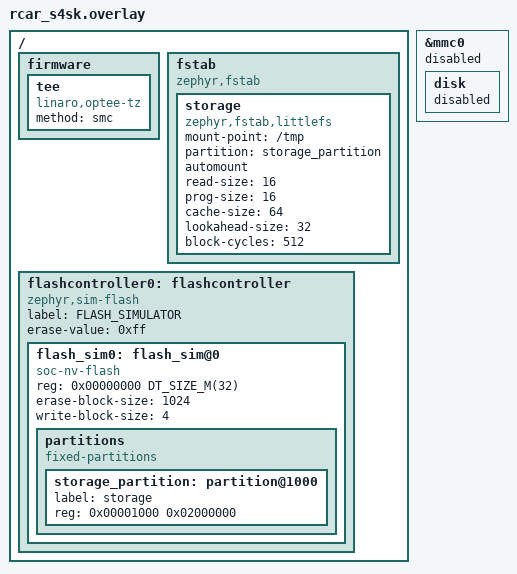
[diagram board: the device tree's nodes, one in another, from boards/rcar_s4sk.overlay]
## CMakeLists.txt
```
#
# Copyright (C) 2023 Renesas Electronics Corporation.
# Copyright (C) 2023 EPAM Systems, Inc.
#
# SPDX-License-Identifier: Apache-2.0
#

cmake_minimum_required(VERSION 3.20.0)

find_package(Zephyr REQUIRED HINTS $ENV{ZEPHYR_BASE})

include($ENV{ZEPHYR_BASE}/cmake/app/boilerplate.cmake NO_POLICY_SCOPE)

project(aoszephyrapp)

# ######################################################################################################################
# Includes
# ######################################################################################################################

zephyr_include_directories(${CMAKE_CURRENT_BINARY_DIR} src)

if(CONFIG_BOARD MATCHES "rcar")
    zephyr_include_directories(${CMAKE_CURRENT_BINARY_DIR} prebuilt)
endif()

if(BOARD MATCHES "native_posix*")
    zephyr_include_directories(${CMAKE_CURRENT_BINARY_DIR} mocks/include)
endif()

if(TA_DEPLOY_DIR)
    set(TA_BIN_DIRECTORY ta_bin)
    set(GENERATED_DIRECTORY ta_table)
    execute_process(
        COMMAND ${CMAKE_CURRENT_SOURCE_DIR}/scripts/prepare_ta.sh -t ${CMAKE_CURRENT_SOURCE_DIR} -f ${TA_DEPLOY_DIR} -b
                ${TA_BIN_DIRECTORY} -g ${GENERATED_DIRECTORY}
    )
    include_directories(app PRIVATE ${CMAKE_CURRENT_SOURCE_DIR}/${TA_BIN_DIRECTORY})
    target_sources(app PRIVATE ${GENERATED_DIRECTORY}/ta_table.c ${GENERATED_DIRECTORY}/ta_table.S)
endif()

# ######################################################################################################################
# Definitions
# ######################################################################################################################

# Aos core configuration
add_definitions(-include aoscoreconfig.hpp)

# ######################################################################################################################
# Compile options
# ######################################################################################################################

# Add stack usage warning
target_compile_options(app PRIVATE -Wstack-usage=2048)

# ######################################################################################################################
# Taget
# ######################################################################################################################

target_sources(
    app
    PRIVATE src/main.cpp
            src/logger/logger.cpp
            src/app/app.cpp
            src/cmclient/cmclient.cpp
            src/runner/runner.cpp
            src/storage/storage.cpp
            src/downloader/downloader.cpp
            src/resourcemanager/resourcemanager.cpp
            src/ocispec/ocispec.cpp
            src/resourceusageprovider/resourceusageprovider.cpp
            src/utils/checksum.cpp
)

# Enable vchannels and xrun mocks for native posix
target_sources_ifdef(CONFIG_NATIVE_APPLICATION app PRIVATE mocks/vch/vch.cpp mocks/xrun/xrun.cpp mocks/xstat/xstat.cpp)

# NOTE: Include source files with DomD binaries and configuration, needed to start DomD on Zephyr
target_sources_ifdef(
    CONFIG_BOARD_RCAR_SPIDER app PRIVATE src/domains/domd/domd_cfg_spider.c src/domains/domd/domain_bins_spider.S
)

target_sources_ifdef(
    CONFIG_BOARD_RCAR_S4SK app PRIVATE src/domains/domd/domd_cfg_s4sk.c src/domains/domd/domain_bins_s4sk.S
)

# NOTE: Include source files for DomD support for Gen3 board.
# Gen3 specific binaries were added with separate .S file to avoid extra checks inside source files.
target_sources_ifdef(
    CONFIG_BOARD_RCAR_SALVATOR_XS_M3 app PRIVATE src/domains/domd/domd_cfg_salvator_xs.c
    src/domains/domd/domain_bins_gen3.S
)

target_sources_ifdef(
    CONFIG_BOARD_RCAR_H3ULCB_CA57 app PRIVATE src/domains/domd/domd_cfg_h3ulcb.c src/domains/domd/domain_bins_gen3.S
)

# NOTE: Include source files for qemu boards.
target_sources_ifdef(CONFIG_BOARD_QEMU_CORTEX_A53 app PRIVATE src/domains/domd/domd_cfg_xenvm.c)

# NOTE: Include HW-specific source file
# target_sources_ifndef(CONFIG_NATIVE_APPLICATION app PRIVATE src/bsp/reboot.c src/bsp/mount.c)
target_sources_ifndef(CONFIG_NATIVE_APPLICATION app PRIVATE src/bsp/reboot.c)

# ######################################################################################################################
# Versioning
# ######################################################################################################################

find_package(Git)

if(NOT GIT_FOUND)
    set(GIT_EXECUTABLE git)
endif()

set(CMAKE_MODULE_PATH ${PROJECT_SOURCE_DIR}/CMakeModules)

add_custom_target(
    version
    COMMAND
        ${CMAKE_COMMAND} -D GIT_EXECUTABLE=${GIT_EXECUTABLE} -D INPUT_FILE=${CMAKE_SOURCE_DIR}/src/version.hpp.in -D
        OUTPUT_FILE=${CMAKE_CURRENT_BINARY_DIR}/version.hpp -D GIT_SOURCE_DIR=${CMAKE_SOURCE_DIR} -P
        ${CMAKE_MODULE_PATH}/GenerateVersion.cmake
)

add_dependencies(app version)

# ######################################################################################################################
#  Generate API
# ######################################################################################################################

find_package(CoreAPI)

generate_api(${CMAKE_CURRENT_SOURCE_DIR}/../aos_core_api)

# ######################################################################################################################
# External libs
# ######################################################################################################################

include(ExternalProject)

zephyr_get_include_directories_for_lang_as_string(CXX includes)
zephyr_get_system_include_directories_for_lang_as_string(CXX system_includes)
zephyr_get_compile_definitions_for_lang_as_string(CXX definitions)
zephyr_get_compile_options_for_lang_as_string(CXX options)

set(external_project_cxx_flags "${includes} ${system_includes} ${definitions} ${options}")

# ######################################################################################################################
# aos_core_lib_cpp
# ######################################################################################################################

set(aos_cxx_flags "${external_project_cxx_flags} -Wno-pedantic -Wno-error -include aoscoreconfig.hpp")
set(aoscore_build_dir ${CMAKE_CURRENT_BINARY_DIR}/aoscore)

ExternalProject_Add(
    aoscore
    PREFIX ${aoscore_build_dir}
    CMAKE_ARGS -DCMAKE_INSTALL_PREFIX=${aoscore_build_dir} -DCMAKE_C_COMPILER=${CMAKE_C_COMPILER}
               -DCMAKE_CXX_COMPILER=${CMAKE_CXX_COMPILER} -DCMAKE_SYSTEM_NAME=${CMAKE_SYSTEM_NAME}
               -DCMAKE_SYSTEM_PROCESSOR=${CMAKE_SYSTEM_PROCESSOR} -DCMAKE_CXX_FLAGS=${aos_cxx_flags}
    SOURCE_DIR ${APPLICATION_SOURCE_DIR}/../aos_core_lib_cpp
    BUILD_BYPRODUCTS ${aoscore_build_dir}/lib/libaossmcpp.a ${aoscore_build_dir}/lib/libaosiamcpp.a
                     ${aoscore_build_dir}/lib/libaoscommoncpp.a
    DEPENDS zephyr_interface
)

# aoscommon
add_library(aoscommon STATIC IMPORTED GLOBAL)

add_dependencies(aoscommon aoscore)

set_target_properties(aoscommon PROPERTIES IMPORTED_LOCATION ${aoscore_build_dir}/lib/libaoscommoncpp.a)
set_target_properties(aoscommon PROPERTIES INTERFACE_INCLUDE_DIRECTORIES ${aoscore_build_dir}/include)

target_link_libraries(app PUBLIC aoscommon)

# aossm
file(MAKE_DIRECTORY ${aoscore_build_dir}/include)

add_library(aossm STATIC IMPORTED GLOBAL)

add_dependencies(aossm aoscore)

set_target_properties(aossm PROPERTIES IMPORTED_LOCATION ${aoscore_build_dir}/lib/libaossmcpp.a)
set_target_properties(aossm PROPERTIES INTERFACE_INCLUDE_DIRECTORIES ${aoscore_build_dir}/include)

target_link_libraries(app PUBLIC aossm)
```

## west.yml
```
#
# Copyright (C) 2023 Renesas Electronics Corporation.
# Copyright (C) 2023 EPAM Systems, Inc.
#
# SPDX-License-Identifier: Apache-2.0
#

# West YAML manifest for Zephyr as Xen Dom0

manifest:
  self:
    path: aos_core_zephyr

  remotes:
    - name: xen-troops
      url-base: https://github.com/xen-troops

    - name: aoscloud
      url-base: https://github.com/aoscloud

    - name: zephyrproject-rtos
      url-base: https://github.com/zephyrproject-rtos

    - name: local
      url-base: /work/zephyr-s4sk/common_data/repo

  projects:
    - name: zephyr
      remote: local
      revision: zephyr-v3.3.0-xt
      west-commands: scripts/west-commands.yml

    - name: aos_core_lib_cpp
      remote: local
      revision: v0.2.1

    - name: aos_core_api
      remote: local
      revision: v7.2.1

    - name: zephyr-xenlib
      remote: local
      revision: ecc874c0b667f9080fb210e1acca25eab4500f6f

    - name: littlefs
      remote: local
      revision: ca583fd297ceb48bced3c2548600dc615d67af24
      path: modules/fs/littlefs
      groups:
        - fs

    - name: nanopb
      remote: local
      revision: 42fa8b211e946b90b9d968523fce7b1cfe27617e
      path: modules/lib/nanopb

    - name: tinycrypt
      remote: local
      revision: 3e9a49d2672ec01435ffbf0d788db6d95ef28de0
      path: modules/crypto/tinycrypt
      groups:
        - crypto

    - name: zephyr-optee-client
      remote: local
      revision: 9e8e574639672d34b6452741b43537cb4b03eb90
```

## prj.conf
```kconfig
#
# Copyright (c) 2023 EPAM Systems
#
# SPDX-License-Identifier: Apache-2.0
#

# ######################################################################################################################
# System params
# ######################################################################################################################

# Set mem parameters
CONFIG_HEAP_MEM_POOL_SIZE=2097152

# Enable userspace
CONFIG_USERSPACE=y

# Set stack size
CONFIG_MAIN_STACK_SIZE=32768

# Select libc
CONFIG_PICOLIBC=y

# Increase KOBJECT RODATA
CONFIG_KOBJECT_RODATA_AREA_EXTRA_BYTES=2048

# ######################################################################################################################
# Enable C++
# ######################################################################################################################

CONFIG_CPP=y
CONFIG_STD_CPP17=y

# ######################################################################################################################
# Logging, errors etc.
# ######################################################################################################################

# Enable logging

CONFIG_LOG=y
CONFIG_LOG_FUNC_NAME_PREFIX_ERR=n
CONFIG_LOG_FUNC_NAME_PREFIX_WRN=n
CONFIG_LOG_FUNC_NAME_PREFIX_INF=n
CONFIG_LOG_FUNC_NAME_PREFIX_DBG=n
#CONFIG_LOG_DEFAULT_LEVEL=3
CONFIG_LOG_DEFAULT_LEVEL=4
CONFIG_LOG_MODE_DEFERRED=y
CONFIG_LOG_BUFFER_SIZE=8192

# Disable FS log to avoid errors duplication. We catch them by Aos errors.
CONFIG_FS_LOG_LEVEL_OFF=y

# Enable assert for debugging purposes
# TODO: remove for release
CONFIG_ASSERT=y

# ######################################################################################################################
# POSIX configuration
# ######################################################################################################################

CONFIG_PTHREAD_IPC=y
CONFIG_POSIX_API=y
CONFIG_POSIX_FS=y
CONFIG_MAX_PTHREAD_COUNT=16
CONFIG_MAX_PTHREAD_MUTEX_COUNT=64
CONFIG_MAX_PTHREAD_COND_COUNT=32
CONFIG_MAX_THREAD_BYTES=3

# ######################################################################################################################
# 3rd parties modules
# ######################################################################################################################

# Enable mbedtls

CONFIG_MBEDTLS=y
CONFIG_MBEDTLS_BUILTIN=y
CONFIG_MBEDTLS_ENABLE_HEAP=y
CONFIG_MBEDTLS_HEAP_SIZE=131072
CONFIG_MBEDTLS_ZEPHYR_ENTROPY=y
CONFIG_MBEDTLS_USER_CONFIG_ENABLE=y
CONFIG_MBEDTLS_USER_CONFIG_FILE="aosmbedtlsconfig.h"

CONFIG_MBEDTLS_CIPHER_CCM_ENABLED=y
CONFIG_MBEDTLS_ECDH_C=y
CONFIG_MBEDTLS_ECDSA_C=y
CONFIG_MBEDTLS_ECP_C=y
CONFIG_MBEDTLS_ECP_DP_SECP256R1_ENABLED=y
CONFIG_MBEDTLS_ECP_DP_SECP384R1_ENABLED=y
CONFIG_MBEDTLS_KEY_EXCHANGE_ECDHE_ECDSA_ENABLED=y
CONFIG_MBEDTLS_KEY_EXCHANGE_RSA_ENABLED=y
CONFIG_MBEDTLS_PEM_CERTIFICATE_FORMAT=y
CONFIG_MBEDTLS_PK_WRITE_C=y
CONFIG_MBEDTLS_PSA_CRYPTO_C=y
CONFIG_MBEDTLS_SSL_MAX_CONTENT_LEN=16384
CONFIG_MBEDTLS_TLS_VERSION_1_2=y

# Enable JSON library

CONFIG_JSON_LIBRARY=y

# Enable nanopb library

CONFIG_NANOPB=y

# ######################################################################################################################
# System components
# ######################################################################################################################

# Enable shell support

CONFIG_SHELL=y
CONFIG_SHELL_BACKEND_SERIAL=y

# Enable file system

CONFIG_FILE_SYSTEM=y
CONFIG_FILE_SYSTEM_SHELL=y
CONFIG_FILE_SYSTEM_LITTLEFS=y

# Configure 

CONFIG_FS_LITTLEFS_CACHE_SIZE=512
CONFIG_FS_LITTLEFS_LOOKAHEAD_SIZE=2048
CONFIG_FS_LITTLEFS_NUM_FILES=8

# Enable FLASH

CONFIG_FLASH=y
CONFIG_FLASH_SHELL=y
CONFIG_FLASH_SIMULATOR=y
CONFIG_FLASH_MAP=y

# Enable cpu power management

CONFIG_PM_CPU_OPS=y

# WA: Disable MMC_DMA to avoid z_mem_phys_add assertion
CONFIG_RCAR_MMC_DMA_SUPPORT=n

# Requires by mbedTLS for entropy. Need to be replaced with HW solution.
CONFIG_TEST_RANDOM_GENERATOR=y

# ######################################################################################################################
# Enable OP-TEE driver and client libraries
# ######################################################################################################################

CONFIG_TEE=y
CONFIG_OPTEE=y

CONFIG_OPTEE_CLIENT=y
CONFIG_OPTEE_LIBTEEC=y
CONFIG_OPTEE_LIBCKTEEC=y
CONFIG_OPTEE_TEE_SUPPLICANT=y
CONFIG_OPTEE_TEE_SUPPLICANT_AUTOINIT=n
CONFIG_OPTEE_STORAGE_ROOT="/aos/tee"

# ######################################################################################################################
# Xen and its components
# ######################################################################################################################

# Enable xen

CONFIG_XEN_DOMAIN_MANAGEMENT=y
CONFIG_XEN_CONSOLE_SRV=y
CONFIG_XEN_STORE_SRV=y
CONFIG_XEN_LIBFDT=y
CONFIG_XEN_SHELL=y

# Enable xrun

CONFIG_XRUN=y
CONFIG_XRUN_SHELL_CMDS=y

# Enable xstat

CONFIG_XSTAT=y
CONFIG_XSTAT_SHELL_CMDS=y

# Enable vchan

CONFIG_XEN_VCH=y
CONFIG_VCH_PATH_MAXLEN=48
```

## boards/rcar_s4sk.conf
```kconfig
#
# Copyright (c) 2023 EPAM Systems
#
# SPDX-License-Identifier: Apache-2.0
#

# Kernel virtual memory size

CONFIG_KERNEL_VM_SIZE=0x4000000
CONFIG_PARTIAL_DEVICE_TREE_SIZE=80000

# Aos config

CONFIG_MINIMAL_LIBC_MALLOC_ARENA_SIZE=8192
CONFIG_FS_LITTLEFS_FC_HEAP_SIZE=8192
CONFIG_SHELL_STACK_SIZE=8192

CONFIG_DISK_ACCESS=y
CONFIG_DISK_DRIVERS=y
CONFIG_DISK_DRIVER_MMC=y

CONFIG_MMC_RCAR=y
CONFIG_MMC_RCA=1

CONFIG_FS_LITTLEFS_BLK_DEV=y

CONFIG_RCAR_MMC_SCC_SUPPORT=n
CONFIG_SD_DATA_TIMEOUT=1000

CONFIG_DEBUG=y
```

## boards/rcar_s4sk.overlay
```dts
/*
 * Copyright (C) 2023 Renesas Electronics Corporation.
 * Copyright (C) 2023 EPAM Systems, Inc.
 *
 * SPDX-License-Identifier: Apache-2.0
 */

#include <mem.h>

&mmc0 {
	disk {
		status = "disabled";
	};
	status = "disabled";
};

/ {
	firmware {
		tee {
		compatible = "linaro,optee-tz";
		method = "smc";
		status = "okay";
		};
	};

	fstab {
		compatible = "zephyr,fstab";
		storage: storage {
			compatible = "zephyr,fstab,littlefs";
			mount-point = "/tmp";
			partition = <&storage_partition>;
			automount;
			read-size = <16>;
			prog-size = <16>;
			cache-size = <64>;
			lookahead-size = <32>;
			block-cycles = <512>;
		};
	};

	flashcontroller0: flashcontroller {
		compatible = "zephyr,sim-flash";
		label = "FLASH_SIMULATOR";
		#address-cells = <1>;
		#size-cells = <1>;
		erase-value = <0xff>;
		flash_sim0: flash_sim@0 {
			compatible = "soc-nv-flash";
			reg = <0x00000000 DT_SIZE_M(32)>;
			erase-block-size = <1024>;
			write-block-size = <4>;
			partitions {
				compatible = "fixed-partitions";
				#address-cells = <1>;
				#size-cells = <1>;
				/*
				* Storage partition will be used by FCB/LittleFS/NVS
				* if enabled.
				*/
				storage_partition: partition@1000 {
					label = "storage";
					reg = <0x00001000 0x02000000>;
				};
			};
		};
	};
};
```

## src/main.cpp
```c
/*
 * Copyright (C) 2023 Renesas Electronics Corporation.
 * Copyright (C) 2023 EPAM Systems, Inc.
 *
 * SPDX-License-Identifier: Apache-2.0
 */

#include <zephyr/sys/__assert.h>
#include <zephyr/sys/printk.h>

#include <aos/common/tools/string.hpp>
#include <aos/common/version.hpp>

#include "app/app.hpp"
#include "logger/logger.hpp"
#include "version.hpp"

#if !defined(CONFIG_NATIVE_APPLICATION)
#include "bsp/mount.h"
#include "bsp/reboot.h"
#include "domains/dom_runner.h"
#endif

int main(void)
{
    printk("*** Aos zephyr application: %s ***\n", AOS_ZEPHYR_APP_VERSION);
    printk("*** Aos core library: %s ***\n", AOS_CORE_VERSION);
    printk("*** Aos core size: %lu ***\n", sizeof(App));

#if !defined(CONFIG_NATIVE_APPLICATION)
    // if (auto ret = littlefs_mount()) {
    //     printk("Failed to mount littlefs (%d)\n", ret);
    // }

    reboot_watcher_init();

    if (auto ret = create_domains()) {
        printk("Failed to create domain (%d)\n", ret);
    }
#endif

    Logger::Init();

    auto& app = App::Get();

    auto err = app.Init();
    __ASSERT(err.IsNone(), "Error initializing application: %s", err.Message());

    return 0;
}
```
